# ATSAM4C16C_0 register map
Vendor: Atmel; Series: SAM4C; File version: 0
CPU: CM4 r0p0, selectable endian, MPU, no FPU, 4 interrupt priority bits
Registers are 32-bit, read-write, reset 0x0 unless marked. A register's access mark holds for its fields unless they carry their own. Offsets are from the block's base; [hi:lo] are bit positions; {n}, {i} and the like mark numbered series; 'fields as' and 'values as' point back to an identical list.

## SUPC — Supply Controller
Base 0x400E1410; register names take the prefix SUPC_
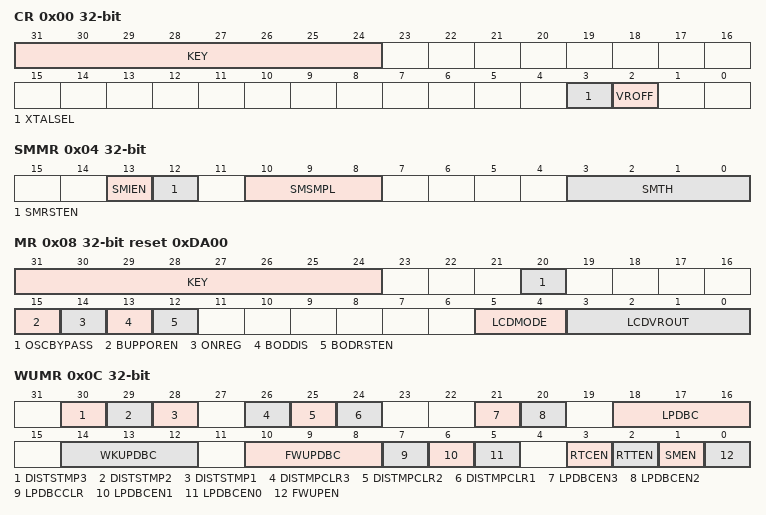
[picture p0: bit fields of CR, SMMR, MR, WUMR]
0x00 CR wo reset not defined — Supply Controller Control Register
  [31:24] KEY — Password
    165=PASSWD (Writing any other value in this field aborts the write operation.)
  [3] XTALSEL — Crystal Oscillator Select
    0=NO_EFFECT; 1=CRYSTAL_SEL (If KEY is correct, switches the slow clock on the crystal oscillator output.)
  [2] VROFF — Voltage Regulator Off
    0=NO_EFFECT; 1=STOP_VREG (If KEY is correct, asserts the system reset signal and stops the voltage regulator.)
0x04 SMMR — Supply Controller Supply Monitor Mode Register
  [13] SMIEN — Supply Monitor Interrupt Enable
    0=NOT_ENABLE (The SUPC interrupt signal is not affected when a supply monitor detection occurs.); 1=ENABLE (The SUPC interrupt signal is asserted when a supply monitor detection occurs.)
  [12] SMRSTEN — Supply Monitor Reset Enable
    0=NOT_ENABLE (The system reset signal is not affected when a supply monitor detection occurs.); 1=ENABLE (The system reset signal is asserted when a supply monitor detection occurs.)
  [10:8] SMSMPL — Supply Monitor Sampling Period
    0=SMD (Supply Monitor disabled); 1=CSM (Continuous Supply Monitor); 2=32SLCK (Supply Monitor enabled one SLCK period every 32 SLCK periods); 3=256SLCK (Supply Monitor enabled one SLCK period every 256 SLCK periods); 4=2048SLCK (Supply Monitor enabled one SLCK period every 2,048 SLCK periods)
  [3:0] SMTH — Supply Monitor Threshold
0x08 MR reset 0xDA00 — Supply Controller Mode Register
  [31:24] KEY — Password Key
    values as CR.KEY
  [20] OSCBYPASS — Oscillator Bypass
    0=NO_EFFECT (No effect. Clock selection depends on XTALSEL value.); 1=BYPASS (The 32 kHz crystal oscillator is bypassed if XTALSEL = 1. OSCBYPASS must be set before setting XTALSEL.)
  [15] BUPPOREN — Backup Area Power-On Reset Enable
    0=BUPPOR_DISABLE (Disables the backup POR.); 1=BUPPOR_ENABLE (Enables the backup POR.)
  [14] ONREG — Voltage Regulator enable
    0=ONREG_UNUSED (Internal voltage regulator is not used (external power supply is used).); 1=ONREG_USED (Internal voltage regulator is used.)
  [13] BODDIS — Brownout Detector Disable
    0=ENABLE (The core brownout detector is enabled.); 1=DISABLE (The core brownout detector is disabled.)
  [12] BODRSTEN — Brownout Detector Reset Enable
    0=NOT_ENABLE (The system reset signal is not affected when a brownout detection occurs.); 1=ENABLE (The system reset signal is asserted when a brownout detection occurs.)
  [5:4] LCDMODE — LCD Controller Mode of Operation
    0=LCDOFF (The internal supply source and the external supply source are both deselected (OFF mode).); 2=LCDON_EXTVR (The external supply source for LCD (VDDLCD) is selected (the LCD voltage regulator is in Hi-Z mode).); 3=LCDON_INVR (The internal supply source for LCD (the LCD Voltage Regulator) is selected (Active mode).)
  [3:0] LCDVROUT — LCD Voltage Regulator Output
0x0C WUMR — Supply Controller Wake-up Mode Register
  [30] DISTSTMP3 — Disable Timestamp from WKUP15/TMP3 Pin
    0=ENABLE (A tamper detection on WKUP15/TMP3 pin generates a timestamp.); 1=DISABLE (A tamper detection on WKUP15/TMP3 does NOT generate a report in timestamp register.)
  [29] DISTSTMP2 — Disable Timestamp from WKUP14/TMP2 Pin
    0=ENABLE (A tamper detection on WKUP14/TMP2 pin generates a timestamp.); 1=DISABLE (A tamper detection on WKUP14/TMP2 does NOT generate a report in timestamp register.)
  [28] DISTSTMP1 — Disable Timestamp from WKUP10/TMP1 Pin
    0=ENABLE (A tamper detection on WKUP10/TMP1 pin generates a timestamp.); 1=DISABLE (A tamper detection on WKUP10/TMP1 does NOT generate a report in timestamp register.)
  [26] DISTMPCLR3 — Disable GPBR Clear Command from WKUP15/TMP3 Pin
    0=ENABLE (The WKUP15/TMP3 input pin can clear the GPBR (if LPDBCCLR is enabled) when tamper is detected.); 1=DISABLE (The WKUP15/TMP3 input pin has no effect on the GPBR value (no clear on tamper detection).)
  [25] DISTMPCLR2 — Disable GPBR Clear Command from WKUP14/TMP2 Pin
    0=ENABLE (The WKUP14/TMP2 input pin can clear the GPBR (if LPDBCCLR is enabled) when tamper is detected.); 1=DISABLE (The WKUP14/TMP2 input pin has no effect on the GPBR value (no clear on tamper detection).)
  [24] DISTMPCLR1 — Disable GPBR Clear Command from WKUP10/TMP1 pin
    0=ENABLE (The WKUP10/TMP1 input pin can clear the GPBR (if LPDBCCLR is enabled) when tamper is detected.); 1=DISABLE (The WKUP10/TMP1 input pin has no effect on the GPBR value (no clear on tamper detection).)
  [21] LPDBCEN3 — Low Power Debouncer Enable WKUP15/TMP3
    0=NOT_ENABLE (The WKUP15/TMP3 input pin is not connected to the low-power debouncer.); 1=ENABLE (The WKUP15/TMP3 input pin is connected to the low-power debouncer and can force a system wake-up.)
  [20] LPDBCEN2 — Low Power Debouncer Enable WKUP14/TMP2
    0=NOT_ENABLE (The WKUP14/TMP2 input pin is not connected to the low-power debouncer.); 1=ENABLE (The WKUP14/TMP2 input pin is connected to the low-power debouncer and can force a system wake-up.)
  [18:16] LPDBC — Low Power Debouncer Period
    0=DISABLE (Disable the low-power debouncers.); {v}={v+1}_RTCOUT0 (WKUP0/10/14/15/TMP0/1/2/3 in active state for at least {v+1} RTCOUT0 periods) (v=1..7)
  [14:12] WKUPDBC — Wake-up Inputs Debouncer Period
    0=IMMEDIATE (Immediate, no debouncing, detected active at least on one Slow Clock edge.); 1=3_SCLK (WKUPx shall be in its active state for at least 3 SLCK periods); 2=32_SCLK (WKUPx shall be in its active state for at least 32 SLCK periods); 3=512_SCLK (WKUPx shall be in its active state for at least 512 SLCK periods); 4=4096_SCLK (WKUPx shall be in its active state for at least 4,096 SLCK periods); 5=32768_SCLK (WKUPx shall be in its active state for at least 32,768 SLCK periods)
  [10:8] FWUPDBC — Force Wake-up Debouncer Period
    0=IMMEDIATE (Immediate, no debouncing, detected active at least on one Slow Clock edge.); 1=3_SCLK (FWUP shall be low for at least 3 SLCK periods); 2=32_SCLK (FWUP shall be low for at least 32 SLCK periods); 3=512_SCLK (FWUP shall be low for at least 512 SLCK periods); 4=4096_SCLK (FWUP shall be low for at least 4,096 SLCK periods); 5=32768_SCLK (FWUP shall be low for at least 32,768 SLCK periods)
  [7] LPDBCCLR — Low-Power Debouncer Clear
    0=NOT_ENABLE (A low-power debounce event does not create an immediate clear on the first half of GPBR registers.); 1=ENABLE (A low-power debounce event on WKUP0/TMP0 or WKUP10/14/15/TMP1/2/3 (if DISTMPCLR1/2/3 is cleared) generates an immediate clear on the first half of GPBR registers.)
  [6] LPDBCEN1 — Low-Power Debouncer Enable WKUP10/TMP1
    0=NOT_ENABLE (The WKUP10/TMP1 input pin is not connected to the low-power debouncer.); 1=ENABLE (The WKUP10/TMP1 input pin is connected to the low-power debouncer and can force a system wake-up.)
  [5] LPDBCEN0 — Low-Power Debouncer Enable WKUP0/TMP0
    0=NOT_ENABLE (The WKUP0/TMP0 input pin is not connected to the low-power debouncer.); 1=ENABLE (The WKUP0/TMP0 input pin is connected to the low-power debouncer and can force a system wake-up.)
  [3] RTCEN — Real-time Clock Wake-up Enable
    0=NOT_ENABLE (The RTC alarm signal has no wake-up effect.); 1=ENABLE (The RTC alarm signal forces a system wake-up.)
  [2] RTTEN — Real-time Timer Wake-up Enable
    0=NOT_ENABLE (The RTT alarm signal has no wake-up effect.); 1=ENABLE (The RTT alarm signal forces a system wake-up.)
  [1] SMEN — Supply Monitor Wake-up Enable
    0=NOT_ENABLE (The supply monitor detection has no wake-up effect.); 1=ENABLE (The supply monitor detection forces a system wake-up.)
  [0] FWUPEN — Force Wake-up Enable
    0=NOT_ENABLE (The force wake-up pin has no wake-up effect.); 1=ENABLE (The force wake-up pin low forces a system wake-up.)
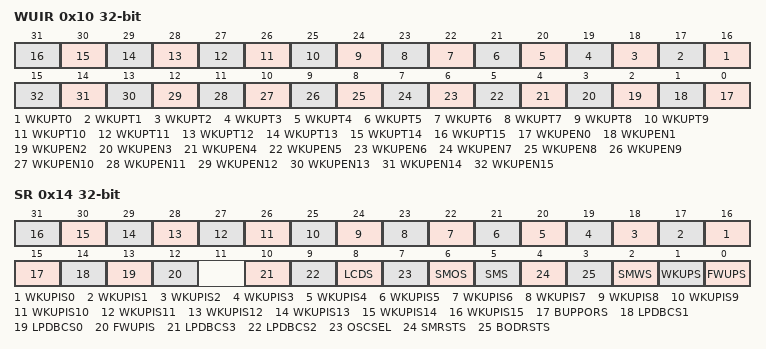
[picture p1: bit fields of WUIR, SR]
0x10 WUIR — Supply Controller Wake-up Inputs Register
  [n+16] WKUPT{n} (n=0..15) — WKUPx Input Type
    0=LOW (A low level for a period defined by WKUPDBC in SUPC_WUMR on the corresponding wake-up input forces a system wake-up.); 1=HIGH (A high level for a period defined by WKUPDBC in SUPC_WUMR on the corresponding wake-up input forces a system wake-up.)
  [n] WKUPEN{n} (n=0..15) — WKUPx Input Enable
    0=DISABLE (The corresponding wake-up input has no wake-up effect.); 1=ENABLE (The corresponding wake-up input forces a system wake-up.)
0x14 SR ro — Supply Controller Status Register
  [n+16] WKUPIS{n} (n=0..15) — WKUPx Input Status (cleared on read)
    0=DIS (The corresponding wake-up input is disabled, or was inactive at the time the debouncer triggered a wake-up event.); 1=EN (The corresponding wake-up input was active at the time the debouncer triggered a wake-up event since the last read of SUPC_SR.)
  [15] BUPPORS — Backup Area Power-On Reset Status
    0=BUPPOR_DISABLED (Backup POR is disabled.); 1=BUPPOR_ENABLED (Backup POR is enabled.)
  [14] LPDBCS1 — Low Power Debouncer Wake-up Status on WKUP10/TMP1 (cleared on read)
    0=NO (No tamper detection or wake-up due to the assertion of the WKUP10 pin has occurred since the last read of SUPC_SR.); 1=PRESENT (At least one tamper detection and wake-up (if enabled by WKUPEN10) due to the assertion of the WKUP10/TMP1 pin has occurred since the last read of SUPC_SR. The SUPC interrupt line is asserted while LPDBCS1 is 1.)
  [13] LPDBCS0 — Low Power Debouncer Wake-up Status on WKUP0/TMP0 (cleared on read)
    0=NO (No tamper detection or wake-up due to the assertion of the WKUP0/TMP0 pin has occurred since the last read of SUPC_SR.); 1=PRESENT (At least one tamper detection and wake-up (if enabled by WKUPEN0) due to the assertion of the WKUP0/TMP0 pin has occurred since the last read of SUPC_SR. The SUPC interrupt line is asserted while LPDBCS0 is 1.)
  [12] FWUPIS — FWUP Input Status
    0=LOW (FWUP input is tied low.); 1=HIGH (FWUP input is tied high.)
  [10] LPDBCS3 — Low Power Debouncer Tamper Status on WKUP15/TMP3 (cleared on read)
    0=NO (No tamper detection or wake-up due to the assertion of the WKUP15/TMP3 pin has occurred since the last read of SUPC_SR.); 1=PRESENT (At least one tamper detection and wake-up (if enabled by WKUPEN15) due to the assertion of the WKUP15/TMP3 pin has occurred since the last read of SUPC_SR. The SUPC interrupt line is asserted while LPDBCS2 is 1.)
  [9] LPDBCS2 — Low Power Debouncer Tamper Status on WKUP14/TMP2 (cleared on read)
    0=NO (No tamper detection or wake-up due to the assertion of the WKUP14/TMP2 pin has occurred since the last read of SUPC_SR.); 1=PRESENT (At least one tamper detection and wake-up (if enabled by WKUPEN14) due to the assertion of the WKUP14/TMP2 pin has occurred since the last read of SUPC_SR. The SUPC interrupt line is asserted while LPDBCS2 is 1.)
  [8] LCDS — LCD Status
    0=DISABLED (LCD controller is disabled.); 1=ENABLED (LCD controller is enabled.)
  [7] OSCSEL — 32 kHz Oscillator Selection Status
    0=RC (The slow clock, SLCK, is generated by the embedded 32 kHz RC oscillator.); 1=CRYST (The slow clock, SLCK, is generated by the 32 kHz crystal oscillator.)
  [6] SMOS — Supply Monitor Output Status
    0=HIGH (The supply monitor detected VDDIO higher than its threshold at its last measurement.); 1=LOW (The supply monitor detected VDDIO lower than its threshold at its last measurement.)
  [5] SMS — Supply Monitor Status (cleared on read)
    0=NO (No supply monitor detection since the last read of SUPC_SR.); 1=PRESENT (At least one supply monitor detection since the last read of SUPC_SR.)
  [4] SMRSTS — Supply Monitor Reset Status (cleared on read)
    0=NO (No supply monitor detection has generated a system reset since the last read of SUPC_SR.); 1=PRESENT (At least one supply monitor detection has generated a system reset since the last read of SUPC_SR.)
  [3] BODRSTS — Brownout Detector Reset Status (cleared on read)
    0=NO (No core brownout rising edge event has been detected since the last read of SUPC_SR.); 1=PRESENT (At least one brownout output rising edge event has been detected since the last read of SUPC_SR.)
  [2] SMWS — Supply Monitor Detection Wake-up Status (cleared on read)
    0=NO (No wake-up due to a supply monitor detection has occurred since the last read of SUPC_SR.); 1=PRESENT (At least one wake-up due to a supply monitor detection has occurred since the last read of SUPC_SR.)
  [1] WKUPS — WKUP Wake-up Status (cleared on read)
    0=NO (No wake-up due to the assertion of the WKUP pins has occurred since the last read of SUPC_SR.); 1=PRESENT (At least one wake-up due to the assertion of the WKUP pins has occurred since the last read of SUPC_SR.)
  [0] FWUPS — FWUP Wake-up Status (cleared on read)
    0=NO (No wake-up due to the assertion of the FWUP pin has occurred since the last read of SUPC_SR.); 1=PRESENT (At least one wake-up due to the assertion of the FWUP pin has occurred since the last read of SUPC_SR.)
